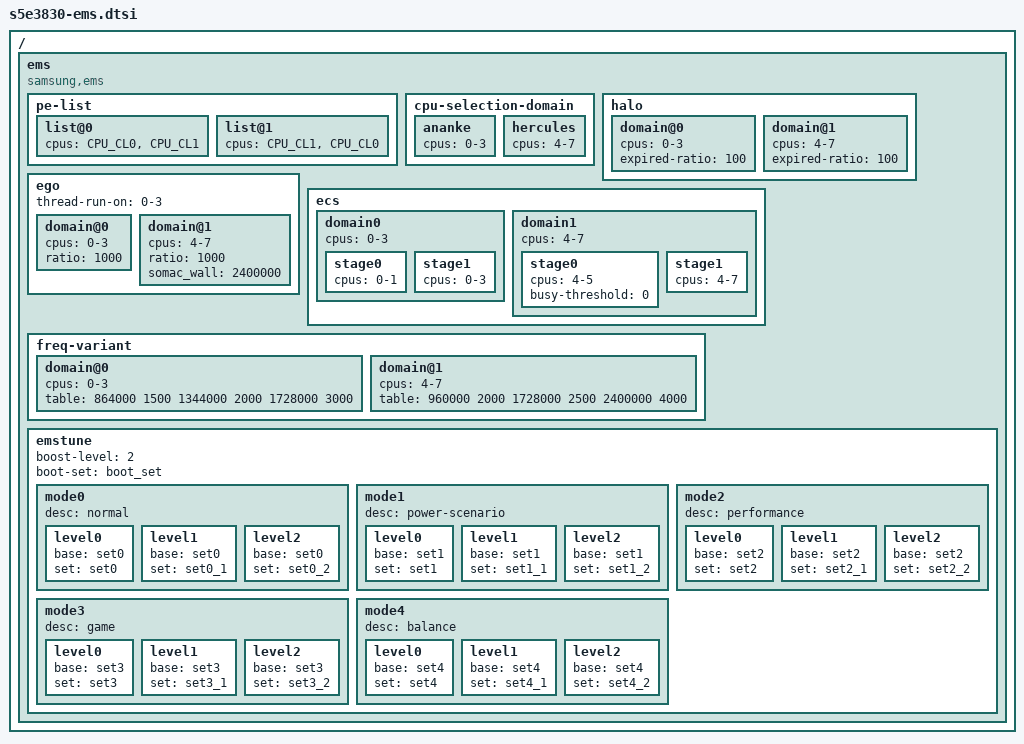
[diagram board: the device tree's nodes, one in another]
/*
 * SAMSUNG EXYNOS SoC EMS device tree source
 *
 * Copyright (c) 2019 Samsung Electronics Co., Ltd.
 *             http://www.samsung.com
 *
 * SAMSUNG EXYNOS SoC EMS device nodes are listed in this file.
 * EXYNOS based board files should include this file.
 *
 * This program is free software; you can redistribute it and/or modify
 * it under the terms of the GNU General Public License version 2 as
 * published by the Free Software Foundation.
 *
 */
#include <dt-bindings/soc/samsung/ems.h>

#include "emstune/s5e3830/sets.dtsi"

/ {
	ems {
		compatible = "samsung,ems";
		status = "okay";

		pe-list {
			#define CPU_CL0 "0-3"
			#define CPU_CL1 "4-7"

			list@0 {
				cpus = CPU_CL0, CPU_CL1;
			};
			list@1 {
				cpus = CPU_CL1, CPU_CL0;
			};
		};

		cpu-selection-domain {
			ananke {
				cpus = "0-3";
			};
			hercules {
				cpus = "4-7";
			};
		};

		halo {
			domain@0 {
				cpus = "0-3";
				expired-ratio = < 100 >;
			};
			domain@1 {
				cpus = "4-7";
				expired-ratio = < 100 >;
			};
		};

		ego {
			thread-run-on = "0-3";

			domain@0 {
				cpus = "0-3";
				ratio = < 1000 >;
			};
			domain@1 {
				cpus = "4-7";
				ratio = < 1000 >;
				somac_wall = <2400000>;
			};
		};

		ecs {
			domain0 {
				cpus = "0-3";

				stage0 {
					cpus = "0-1";
				};
				stage1 {
					cpus = "0-3";
				};
			};
			domain1 {
				cpus = "4-7";

				stage0 {
					cpus = "4-5";
					busy-threshold = <0>;
				};
				stage1 {
					cpus = "4-7";
				};
			};
		};

		freq-variant {
			domain@0 {
				cpus = "0-3";
					/* Freq	  Resi */
				table = < 864000  1500
					  1344000 2000
					  1728000 3000 >;
			};
			domain@1 {
				cpus = "4-7";
					/* Freq	  Resi */
				table = < 960000  2000
					  1728000 2500
					  2400000 4000 >;
			};
		};

		emstune {
			boost-level = <2>;
			boot-set = <&boot_set>;

			mode0 {
				desc = "normal";

				level0 {
					base = <&set0>;
					set = <&set0>;
				};
				level1 {
					base = <&set0>;
					set = <&set0_1>;
				};
				level2 {
					base = <&set0>;
					set = <&set0_2>;
				};
			};
			mode1 {
				desc = "power-scenario";

				level0 {
					base = <&set1>;
					set = <&set1>;
				};
				level1 {
					base = <&set1>;
					set = <&set1_1>;
				};
				level2 {
					base = <&set1>;
					set = <&set1_2>;
				};
			};
			mode2 {
				desc = "performance";

				level0 {
					base = <&set2>;
					set = <&set2>;
				};
				level1 {
					base = <&set2>;
					set = <&set2_1>;
				};
				level2 {
					base = <&set2>;
					set = <&set2_2>;
				};
			};
			mode3 {
				desc = "game";

				level0 {
					base = <&set3>;
					set = <&set3>;
				};
				level1 {
					base = <&set3>;
					set = <&set3_1>;
				};
				level2 {
					base = <&set3>;
					set = <&set3_2>;
				};
			};
			mode4 {
				desc = "balance";

				level0 {
					base = <&set4>;
					set = <&set4>;
				};
				level1 {
					base = <&set4>;
					set = <&set4_1>;
				};
				level2 {
					base = <&set4>;
					set = <&set4_2>;
				};
			};
		};
	};
};
